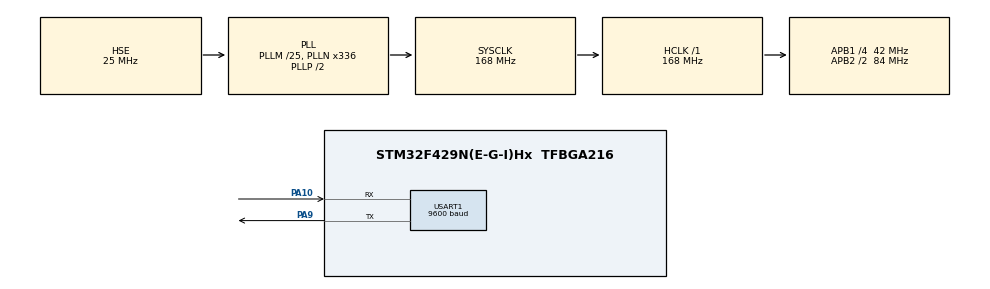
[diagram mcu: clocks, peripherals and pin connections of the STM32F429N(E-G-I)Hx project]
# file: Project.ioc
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Mcu.Family=STM32F4
Mcu.Name=STM32F429N(E-G-I)Hx
Mcu.Package=TFBGA216
NVIC.PriorityGroup=NVIC_PRIORITYGROUP_4
NVIC.USART1_IRQn=true\:0\:0
PA10.Mode=Asynchronous
PA10.Signal=USART1_RX
PA9.Mode=Asynchronous
PA9.Signal=USART1_TX
PH0/OSC_IN.Mode=HSE-External-Oscillator
PH0/OSC_IN.Signal=RCC_OSC_IN
PH1/OSC_OUT.Mode=HSE-External-Oscillator
PH1/OSC_OUT.Signal=RCC_OSC_OUT
ProjectManager.TargetToolchain=EWARM 6.70
RCC.48MHZClocksFreq_Value=84000000
RCC.AHBFreq_Value=168000000
RCC.APB1CLKDivider=RCC_HCLK_DIV4
RCC.APB1Freq_Value=42000000
RCC.APB1TimFreq_Value=84000000
RCC.APB2CLKDivider=RCC_HCLK_DIV2
RCC.APB2Freq_Value=84000000
RCC.APB2TimFreq_Value=168000000
RCC.ClockTypePCLK1-ClockTree=RCC_CLOCKTYPE_PCLK1
RCC.ClockTypePCLK2-ClockTree=RCC_CLOCKTYPE_PCLK2
RCC.ClockTypeSysClk-ClockTree=RCC_CLOCKTYPE_SYSCLK
RCC.CortexFreq_Value=21000000
RCC.EnableExtClockForI2S-ClockTree=false
RCC.EnableExtClockForSAIA-ClockTree=false
RCC.EnableExtClockForSAIB-ClockTree=false
RCC.EnableHSE-ClockTree=true
RCC.EnableHSERTCDevisor-ClockTree=false
RCC.EnableLSE-ClockTree=false
RCC.EnableLSERTC-ClockTree=false
RCC.ExtClockEnable-ClockTree=false
RCC.FLatency-AdvancedSettings=FLASH_LATENCY_5
RCC.HCLKFreq_Value=168000000
RCC.HSEState-ClockTree=RCC_HSE_ON
RCC.HSE_VALUE=25000000
RCC.HSIState-ClockTree=RCC_HSI_OFF
RCC.HSI_VALUE=16000000
RCC.I2SEnable-ClockTree=false
RCC.IWDGEnable-ClockTree=false
RCC.LSE_VALUE=32768
RCC.LSIState-ClockTree=RCC_LSI_OFF
RCC.LTDCEnable-ClockTree=false
RCC.MCO1OutPutEnable-ClockTree=false
RCC.MCO2OutPutEnable-ClockTree=false
RCC.OscillatorTypeHSE-ClockTree=RCC_OSCILLATORTYPE_HSE
RCC.PLLI2SCLKSAIA_BEnable-ClockTree=false
RCC.PLLM=25
RCC.PLLN=336
RCC.PLLSourceVirtual=RCC_PLLSOURCE_HSE
RCC.PLLState-ClockTree=RCC_PLL_ON
RCC.PWR_Regulator_Voltage_Scale-AdvancedSettings=PWR_REGULATOR_VOLTAGE_SCALE1
RCC.RNGEnable-ClockTree=false
RCC.RTCEnable-ClockTree=false
RCC.SAIAEnable-ClockTree=false
RCC.SAIBEnable-ClockTree=false
RCC.SDIOEnable-ClockTree=false
RCC.SYSCLKFreq_VALUE=168000000
RCC.SYSCLKSource=RCC_SYSCLKSOURCE_PLLCLK
RCC.USBFSEnable-ClockTree=false
RCC.USBHSEnable-ClockTree=false
RCC.VCOOutputFreq_Value=336000000
USART1.BaudRate=9600
USART1.HwFlowCtl-Asynchronous=UART_HWCONTROL_NONE
USART1.Parity-Asynchronous=UART_PARITY_NONE
USART1.VirtualMode-Asynchronous=VM_ASYNC

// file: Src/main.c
/**
  ******************************************************************************
  * File Name          : main.c
  * Date               : 19/09/2014 15:43:11
  * Description        : Main program body
  ******************************************************************************
  *
  * COPYRIGHT(c) 2014 STMicroelectronics
  *
  * Redistribution and use in source and binary forms, with or without modification,
  * are permitted provided that the following conditions are met:
  *   1. Redistributions of source code must retain the above copyright notice,
  *      this list of conditions and the following disclaimer.
  *   2. Redistributions in binary form must reproduce the above copyright notice,
  *      this list of conditions and the following disclaimer in the documentation
  *      and/or other materials provided with the distribution.
  *   3. Neither the name of STMicroelectronics nor the names of its contributors
  *      may be used to endorse or promote products derived from this software
  *      without specific prior written permission.
  *
  * THIS SOFTWARE IS PROVIDED BY THE COPYRIGHT HOLDERS AND CONTRIBUTORS "AS IS"
  * AND ANY EXPRESS OR IMPLIED WARRANTIES, INCLUDING, BUT NOT LIMITED TO, THE
  * IMPLIED WARRANTIES OF MERCHANTABILITY AND FITNESS FOR A PARTICULAR PURPOSE ARE
  * DISCLAIMED. IN NO EVENT SHALL THE COPYRIGHT HOLDER OR CONTRIBUTORS BE LIABLE
  * FOR ANY DIRECT, INDIRECT, INCIDENTAL, SPECIAL, EXEMPLARY, OR CONSEQUENTIAL
  * DAMAGES (INCLUDING, BUT NOT LIMITED TO, PROCUREMENT OF SUBSTITUTE GOODS OR
  * SERVICES; LOSS OF USE, DATA, OR PROFITS; OR BUSINESS INTERRUPTION) HOWEVER
  * CAUSED AND ON ANY THEORY OF LIABILITY, WHETHER IN CONTRACT, STRICT LIABILITY,
  * OR TORT (INCLUDING NEGLIGENCE OR OTHERWISE) ARISING IN ANY WAY OUT OF THE USE
  * OF THIS SOFTWARE, EVEN IF ADVISED OF THE POSSIBILITY OF SUCH DAMAGE.
  *
  ******************************************************************************
  */

#include "stm32f4xx_hal.h"

/* USER CODE BEGIN Includes */
#include "stdlib.h"
#define BufferSize(_BUFFER_) sizeof(_BUFFER_)/sizeof(*(_BUFFER_))
/* USER CODE END Includes */

UART_HandleTypeDef huart1;

/* USER CODE BEGIN PV */

uint8_t reception[1] ="";

/* USER CODE END PV */

void SystemClock_Config(void);
static void MX_GPIO_Init(void);
static void MX_USART1_UART_Init(void);

int main(void)
{

  /* MCU Configuration----------------------------------------------------------*/

  /* Reset of all peripherals, Initializes the Flash interface and the Systick. */
  HAL_Init();

  /* Configure the system clock */
  SystemClock_Config();

  /* Initialize all configured peripherals */
  MX_GPIO_Init();
  MX_USART1_UART_Init();

  /* USER CODE BEGIN 2 */
  uint8_t transmition[] = "\n\r Welcome to UART Test Please enter some characters and press send \n\r";
  HAL_UART_Transmit_IT(&huart1, (uint8_t*)transmition, BufferSize(transmition));

  while (HAL_UART_GetState(&huart1) != HAL_UART_STATE_READY)
  {
  }

  /* USER CODE END 2 */

  /* USER CODE BEGIN 3 */
  HAL_UART_Receive_IT(&huart1, (uint8_t *)reception, 1/*BufferSize(reception) = 1*/);

  /* Infinite loop */
  while (1)
  {

    /* USER CODE END 3 */

  }
}
/** System Clock Configuration
*/
void SystemClock_Config(void)
{

  RCC_OscInitTypeDef RCC_OscInitStruct;
  RCC_ClkInitTypeDef RCC_ClkInitStruct;

  __PWR_CLK_ENABLE();

  __HAL_PWR_VOLTAGESCALING_CONFIG(PWR_REGULATOR_VOLTAGE_SCALE1);

  RCC_OscInitStruct.OscillatorType = RCC_OSCILLATORTYPE_HSE;
  RCC_OscInitStruct.HSEState = RCC_HSE_ON;
  RCC_OscInitStruct.PLL.PLLState = RCC_PLL_ON;
  RCC_OscInitStruct.PLL.PLLSource = RCC_PLLSOURCE_HSE;
  RCC_OscInitStruct.PLL.PLLM = 25;
  RCC_OscInitStruct.PLL.PLLN = 336;
  RCC_OscInitStruct.PLL.PLLP = RCC_PLLP_DIV2;
  RCC_OscInitStruct.PLL.PLLQ = 4;
  HAL_RCC_OscConfig(&RCC_OscInitStruct);

  RCC_ClkInitStruct.ClockType = RCC_CLOCKTYPE_SYSCLK|RCC_CLOCKTYPE_PCLK1
                              |RCC_CLOCKTYPE_PCLK2;
  RCC_ClkInitStruct.SYSCLKSource = RCC_SYSCLKSOURCE_PLLCLK;
  RCC_ClkInitStruct.AHBCLKDivider = RCC_SYSCLK_DIV1;
  RCC_ClkInitStruct.APB1CLKDivider = RCC_HCLK_DIV4;
  RCC_ClkInitStruct.APB2CLKDivider = RCC_HCLK_DIV2;
  HAL_RCC_ClockConfig(&RCC_ClkInitStruct, FLASH_LATENCY_5);

}

/* USART1 init function */
void MX_USART1_UART_Init(void)
{

  huart1.Instance = USART1;
  huart1.Init.BaudRate = 9600;
  huart1.Init.WordLength = UART_WORDLENGTH_8B;
  huart1.Init.StopBits = UART_STOPBITS_1;
  huart1.Init.Parity = UART_PARITY_NONE;
  huart1.Init.Mode = UART_MODE_TX_RX;
  huart1.Init.HwFlowCtl = UART_HWCONTROL_NONE;
  huart1.Init.OverSampling = UART_OVERSAMPLING_16;
  HAL_UART_Init(&huart1);

}

/** Configure pins as
        * Analog
        * Input
        * Output
        * EVENT_OUT
        * EXTI
*/
void MX_GPIO_Init(void)
{

  /* GPIO Ports Clock Enable */
  __GPIOA_CLK_ENABLE();
  __GPIOH_CLK_ENABLE();

}

/* USER CODE BEGIN 4 */
void HAL_UART_RxCpltCallback(UART_HandleTypeDef *huart)
{
  /* NOTE: This function Should not be modified, when the callback is needed,
           the HAL_UART_TxCpltCallback could be implemented in the user file
   */
   HAL_UART_Receive_IT(&huart1, (uint8_t *)reception, 1/*BufferSize(reception)*/);
   USART1->DR = reception[0];
}
/* USER CODE END 4 */

/************************ (C) COPYRIGHT STMicroelectronics *****END OF FILE****/
